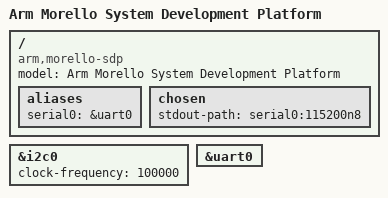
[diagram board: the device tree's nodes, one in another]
// SPDX-License-Identifier: (GPL-2.0 OR BSD-3-Clause)
/*
 * Copyright (c) 2021-2024, Arm Limited. All rights reserved.

 */

/dts-v1/;
#include "morello.dtsi"

/ {
	model = "Arm Morello System Development Platform";
	compatible = "arm,morello-sdp", "arm,morello";

	aliases {
		serial0 = &uart0;
	};

	chosen {
		stdout-path = "serial0:115200n8";
	};
};

&i2c0 {
	clock-frequency = <100000>;
	status = "okay";
};

&uart0 {
	status = "okay";
};
